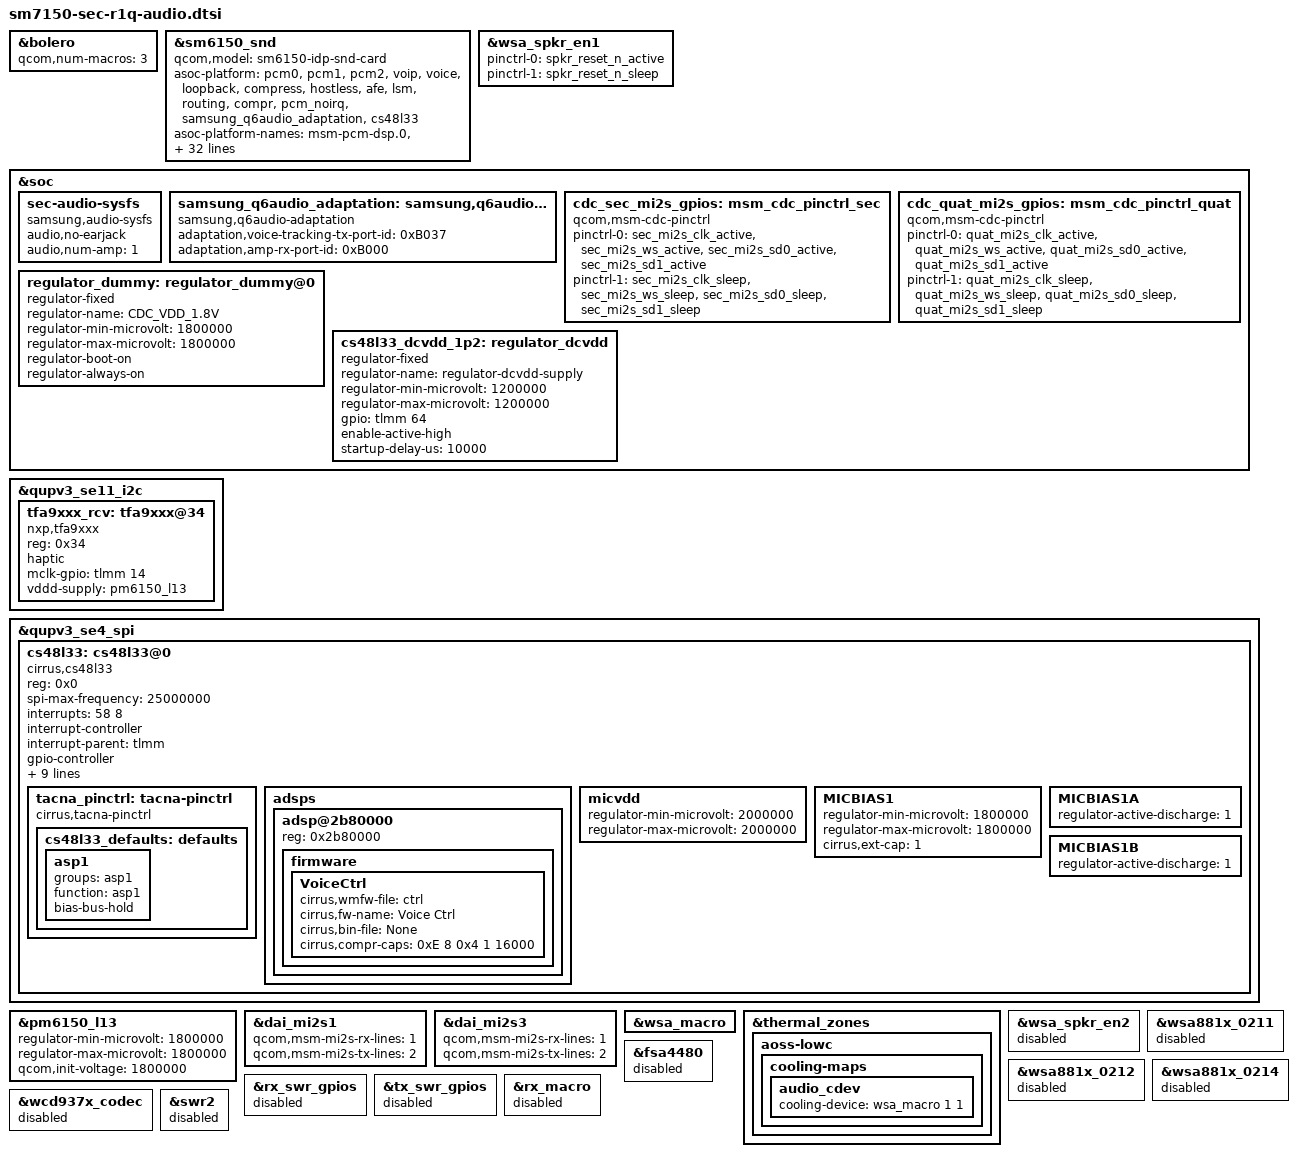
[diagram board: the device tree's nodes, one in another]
/* Copyright (c) 2018, The Linux Foundation. All rights reserved.
 *
 * This program is free software; you can redistribute it and/or modify
 * it under the terms of the GNU General Public License version 2 and
 * only version 2 as published by the Free Software Foundation.
 *
 * This program is distributed in the hope that it will be useful,
 * but WITHOUT ANY WARRANTY; without even the implied warranty of
 * MERCHANTABILITY or FITNESS FOR A PARTICULAR PURPOSE.  See the
 * GNU General Public License for more details.
 */

&bolero {
	qcom,num-macros = <3>;
};

&sm6150_snd {
	qcom,model = "sm6150-idp-snd-card";

	asoc-platform = <&pcm0>, <&pcm1>, <&pcm2>, <&voip>, <&voice>,
			<&loopback>, <&compress>, <&hostless>,
			<&afe>, <&lsm>, <&routing>, <&compr>,
			<&pcm_noirq>, <&samsung_q6audio_adaptation>,
			<&cs48l33>;
	asoc-platform-names = "msm-pcm-dsp.0", "msm-pcm-dsp.1",
			"msm-pcm-dsp.2", "msm-voip-dsp",
			"msm-pcm-voice", "msm-pcm-loopback",
			"msm-compress-dsp", "msm-pcm-hostless",
			"msm-pcm-afe", "msm-lsm-client",
			"msm-pcm-routing", "msm-compr-dsp",
			"msm-pcm-dsp-noirq", "q6audio-adaptation",
			"cs48l32-codec";
	qcom,audio-routing =
		"AMIC1", "MIC BIAS1",
		"MIC BIAS1", "Analog Mic1",
		"AMIC2", "MIC BIAS2",
		"MIC BIAS2", "Analog Mic2",
		"SYSCLK", "FLL1",
		"TX SWR_ADC0", "ADC1_OUTPUT",
		"TX SWR_ADC2", "ADC2_OUTPUT",
		"WSA SRC0_INP", "SRC0",
		"WSA_TX DEC0_INP", "TX DEC0 MUX",
		"WSA_TX DEC1_INP", "TX DEC1 MUX",
		"RX_TX DEC0_INP", "TX DEC0 MUX",
		"RX_TX DEC1_INP", "TX DEC1 MUX",
		"RX_TX DEC2_INP", "TX DEC2 MUX",
		"RX_TX DEC3_INP", "TX DEC3 MUX",
		"SpkrLeft IN", "WSA_SPK1 OUT";
	qcom,msm-mbhc-hphl-swh = <0>;
	qcom,msm-mbhc-gnd-swh = <0>;
	qcom,cdc-dmic01-gpios = <0>;
	qcom,cdc-dmic23-gpios = <0>;
	qcom,fm-lna-gpios = <&expander_gpios 20 0>;

	qcom,sec-mi2s-gpios = <&cdc_sec_mi2s_gpios>;
	qcom,quat-mi2s-gpios = <&cdc_quat_mi2s_gpios>;
	qcom,wsa-max-devs = <1>;
	qcom,wsa-devs = <&wsa881x_0213>;
	qcom,wsa-aux-dev-prefix = "SpkrLeft";
	qcom,codec-max-aux-devs = <0>;

	cirrus,sysclk = <1 4 98304000>;
	cirrus,fll1-refclk = <1 0 32768 49152000>;
	cirrus,fll1-refclk-bclk = <1 8 0 49152000>;
};

&wsa_spkr_en1 {
	pinctrl-0 = <&spkr_reset_n_active>;
	pinctrl-1 = <&spkr_reset_n_sleep>;
};

&soc {
	sec-audio-sysfs {
		compatible = "samsung,audio-sysfs";
		status = "okay";
		audio,no-earjack;
		audio,num-amp = <1>;
	};
	samsung_q6audio_adaptation: samsung,q6audio-adaptation {
		compatible = "samsung,q6audio-adaptation";
		adaptation,voice-tracking-tx-port-id = <0xB037>;
		adaptation,amp-rx-port-id = <0xB000>;
	};

	cdc_sec_mi2s_gpios: msm_cdc_pinctrl_sec {
		compatible = "qcom,msm-cdc-pinctrl";
		pinctrl-names = "aud_active", "aud_sleep";
		pinctrl-0 = <&sec_mi2s_clk_active &sec_mi2s_ws_active
				 &sec_mi2s_sd0_active &sec_mi2s_sd1_active>;
		pinctrl-1 = <&sec_mi2s_clk_sleep &sec_mi2s_ws_sleep
				 &sec_mi2s_sd0_sleep &sec_mi2s_sd1_sleep>;
	};

	cdc_quat_mi2s_gpios: msm_cdc_pinctrl_quat {
		compatible = "qcom,msm-cdc-pinctrl";
		pinctrl-names = "aud_active", "aud_sleep";
		pinctrl-0 = <&quat_mi2s_clk_active &quat_mi2s_ws_active
			     &quat_mi2s_sd0_active &quat_mi2s_sd1_active>;
		pinctrl-1 = <&quat_mi2s_clk_sleep &quat_mi2s_ws_sleep
			     &quat_mi2s_sd0_sleep &quat_mi2s_sd1_sleep>;
	};

	regulator_dummy: regulator_dummy@0 {
		compatible = "regulator-fixed";

		regulator-name = "CDC_VDD_1.8V";
		regulator-min-microvolt = <1800000>;
		regulator-max-microvolt = <1800000>;
		regulator-boot-on;
		regulator-always-on;
	};

	cs48l33_dcvdd_1p2: regulator_dcvdd {
		compatible = "regulator-fixed";
		regulator-name = "regulator-dcvdd-supply";
		status = "ok";
		regulator-min-microvolt = <1200000>;
		regulator-max-microvolt = <1200000>;
		gpio = <&tlmm 64 0>; /* VOICE_LDO_ENABLE */
		enable-active-high;
		startup-delay-us = <10000>;
	};
};

&qupv3_se11_i2c {
	status = "okay";
	tfa9xxx_rcv: tfa9xxx@34 {
	compatible = "nxp,tfa9xxx";
	reg = <0x34>;
	haptic; /* this device has the LRA */
	mclk-gpio = <&tlmm 14 0>;
	vddd-supply = <&pm6150_l13>;
	
    };
};

&qupv3_se4_spi {
	status = "okay";

	cs48l33: cs48l33@0 {
		compatible = "cirrus,cs48l33";
		reg = <0x0>;

		spi-max-frequency = <25000000>;

		interrupts = <58 8>;
		interrupt-controller;
		#interrupt-cells = <2>;
		interrupt-parent = <&tlmm>;
		gpio-controller;
		#gpio-cells = <2>;
		#sound-dai-cells = <1>;

		VDD_A-supply = <&regulator_dummy>;
		VDD_IO1-supply = <&regulator_dummy>;
		VDD1_CP-supply = <&regulator_dummy>;
		VDD_D-supply = <&cs48l33_dcvdd_1p2>;

		reset-gpios = <&tlmm 68 0>;

		cirrus,in-type = <
			0 0 0 0 /* IN1 */
		>;

		pinctrl-names = "active", "sleep";
		pinctrl-0 = <&cs48l33_defaults &cs48l33_int_default>;
		pinctrl-1 = <&cs48l33_ldo_sleep>;

		tacna_pinctrl: tacna-pinctrl {
			compatible = "cirrus,tacna-pinctrl";

			cs48l33_defaults: defaults {
				asp1 {
					groups = "asp1";
					function = "asp1";
					bias-bus-hold;
				};
			};
		};

		adsps {
			#address-cells = <1>;
			#size-cells = <0>;

			adsp@2b80000 {
				reg = <0x2b80000>;
				firmware {
					VoiceCtrl {
						cirrus,wmfw-file = "ctrl";
						cirrus,fw-name = "Voice Ctrl";
						cirrus,bin-file = "None";
						cirrus,compr-caps = <0xE 8 0x4 1 16000>;
					};
				};
			};
		};

		micvdd {
			regulator-min-microvolt = <2000000>;
			regulator-max-microvolt = <2000000>;
		};

		MICBIAS1 {
			regulator-min-microvolt = <1800000>;
			regulator-max-microvolt = <1800000>;
			cirrus,ext-cap = <1>;
		};

		MICBIAS1A {
			regulator-active-discharge = <1>;
		};

		MICBIAS1B {
			regulator-active-discharge = <1>;
		};
	};
};

&pm6150_l13 {
	regulator-min-microvolt = <1800000>;
	regulator-max-microvolt = <1800000>;
	qcom,init-voltage = <1800000>;
};

&dai_mi2s1 {
	qcom,msm-mi2s-rx-lines = <1>;
	qcom,msm-mi2s-tx-lines = <2>;
};

&dai_mi2s3 {
	qcom,msm-mi2s-rx-lines = <1>;
	qcom,msm-mi2s-tx-lines = <2>;
};

&wsa_macro {
	#cooling-cells = <2>;
};

&thermal_zones {
	aoss-lowc {
		cooling-maps {
			audio_cdev {
				cooling-device = <&wsa_macro 1 1>;
			};
		};
	};
};

&wsa_spkr_en2 {
	status = "disabled";
};
&wsa881x_0211 {
	status = "disabled";
};
&wsa881x_0212 {
	status = "disabled";
};
&wsa881x_0214 {
	status = "disabled";
};
&fsa4480 {
	status = "disabled";
};
&rx_swr_gpios {
	status = "disabled";
};

&tx_swr_gpios {
	status = "disabled";
};

&rx_macro {
	status = "disabled";
};

&wcd937x_codec {
	status = "disabled";
};

&swr2 {
	status = "disabled";
};
